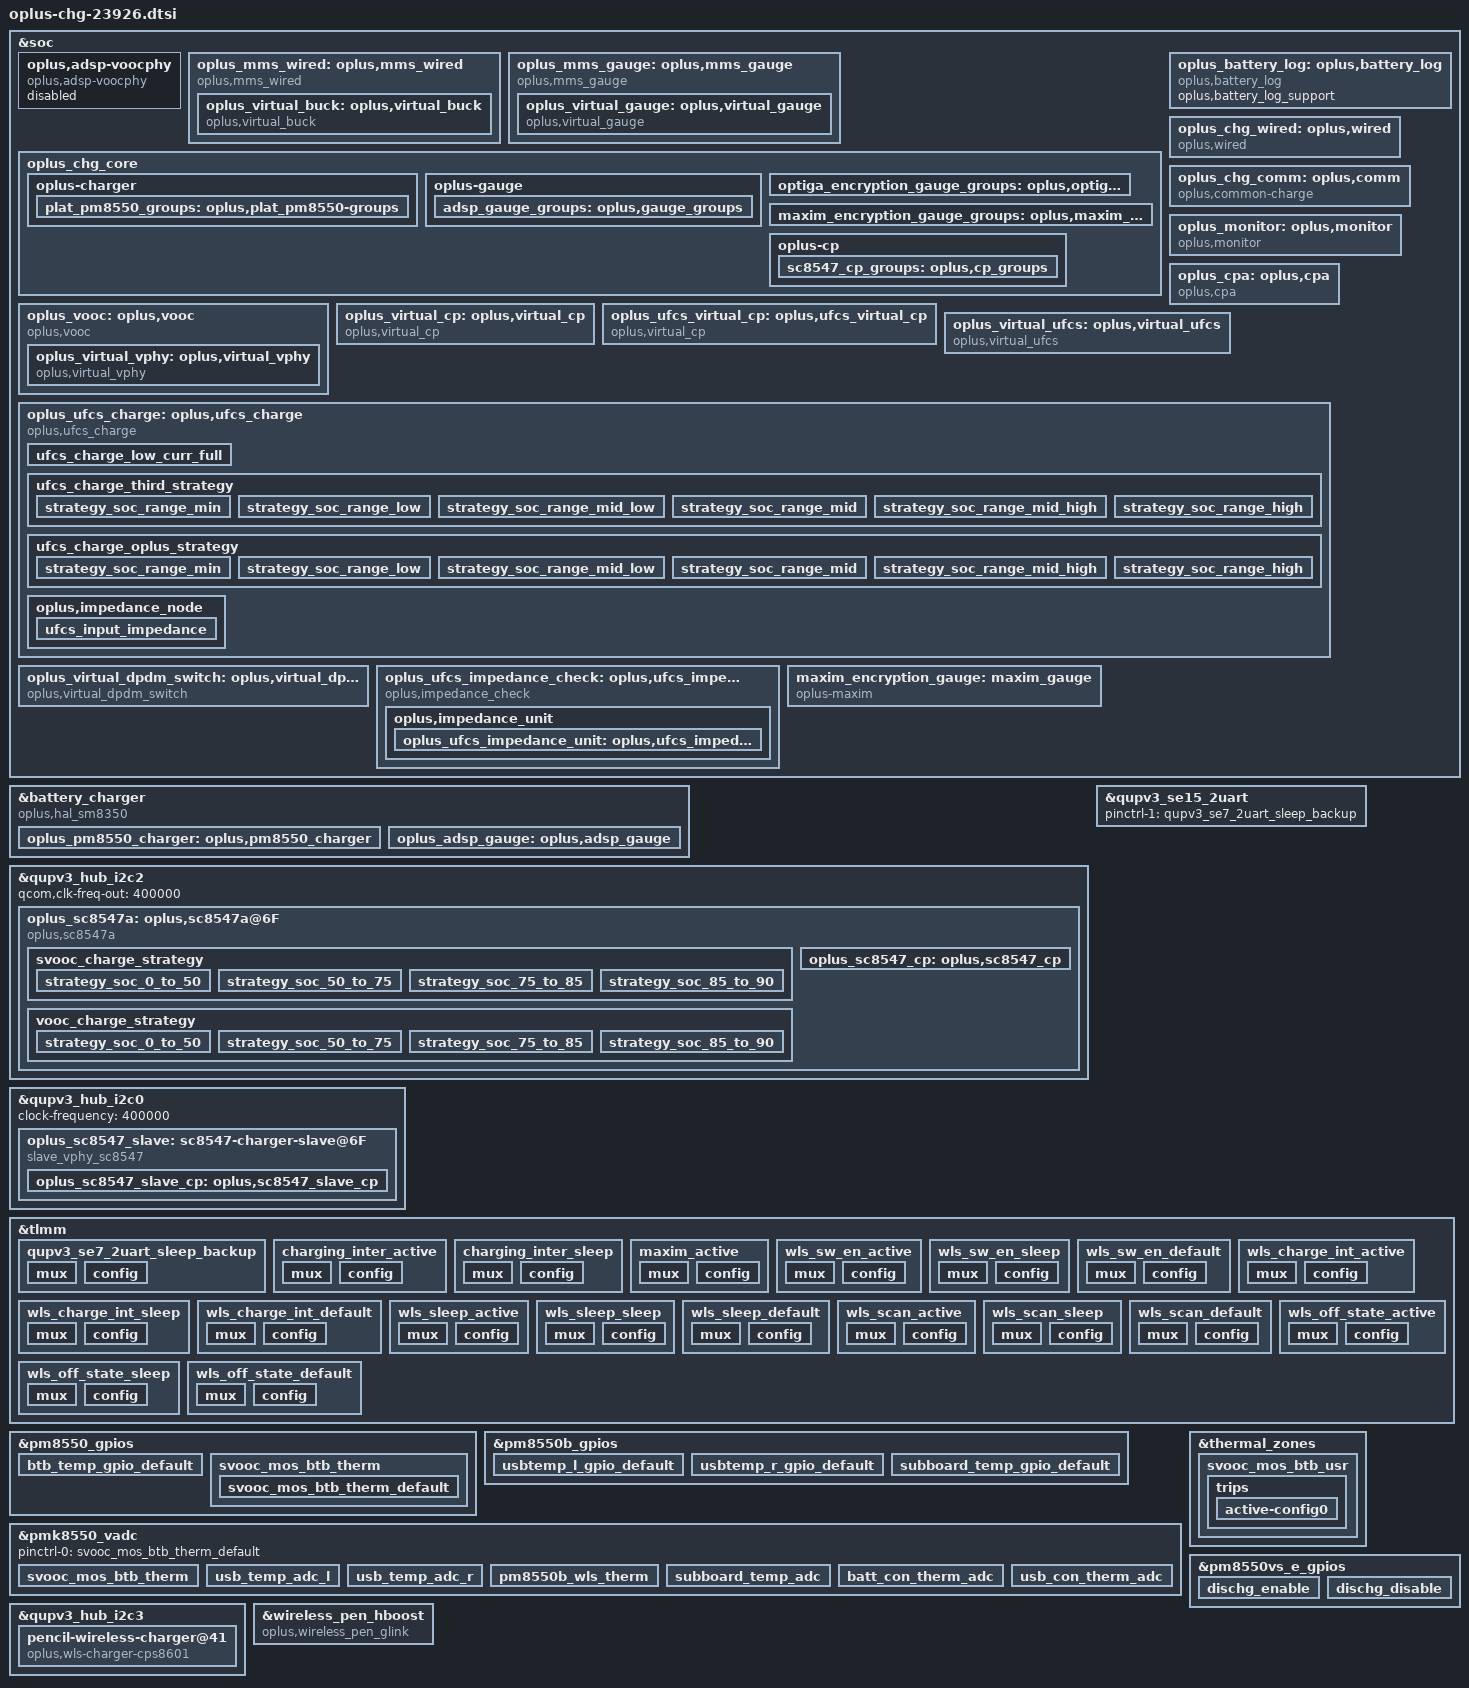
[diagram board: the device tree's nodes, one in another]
//ifdef OPLUS_FEATURE_CHG_BASIC
//BSP.CHG.Basic, 2023/12/22,  Add for charging

#include "oplus-chg-8650.h.dtsi"

&soc {
	oplus,adsp-voocphy {
		status = "disabled";
		compatible = "oplus,adsp-voocphy";
	};

	oplus_mms_wired: oplus,mms_wired {
		compatible = "oplus,mms_wired";
		oplus,buck_ic = <&oplus_virtual_buck>;
		oplus,voocphy_ic = <&oplus_virtual_vphy>;
		oplus,usbtemp_batttemp_gap = <12>;
		oplus,adc_info_name = "855";
		oplus,topic-update-interval = <5000>;

		/* High temperature long-term solution for Battery bulge*/
		high-temp-scheme;
		oplus,support_usbtemp_protect_v2;
		oplus_spec,usbtemp_batt_temp_low = <50>;
		oplus_spec,usbtemp_batt_temp_high = <50>;
		oplus_spec,usbtemp_batt_temp_over_hot = <60>;
		oplus_spec,usbtemp_ntc_temp_low = <57>;
		oplus_spec,usbtemp_ntc_temp_high = <69>;
		oplus_spec,usbtemp_temp_gap_low_with_batt_temp = <7>;
		oplus_spec,usbtemp_temp_gap_with_batt_temp_in_over_hot = <15>;
		oplus_spec,usbtemp_temp_gap_high_with_batt_temp = <12>;
		oplus_spec,usbtemp_temp_gap_low_without_batt_temp = <12>;
		oplus_spec,usbtemp_temp_gap_high_without_batt_temp = <24>;
		oplus_spec,usbtemp_rise_fast_temp_low = <3>;
		oplus_spec,usbtemp_rise_fast_temp_high = <3>;
		oplus_spec,usbtemp_rise_fast_temp_count_low = <30>;
		oplus_spec,usbtemp_rise_fast_temp_count_high = <20>;
		oplus_spec,usbtemp_cool_down_ntc_low = <54>;
		oplus_spec,usbtemp_cool_down_ntc_high = <65>;
		oplus_spec,usbtemp_cool_down_gap_low = <12>;
		oplus_spec,usbtemp_cool_down_gap_high = <20>;
		oplus_spec,usbtemp_cool_down_recover_ntc_low = <48>;
		oplus_spec,usbtemp_cool_down_recover_ntc_high = <60>;
		oplus_spec,usbtemp_cool_down_recover_gap_low = <6>;
		oplus_spec,usbtemp_cool_down_recover_gap_high = <15>;

		oplus_virtual_buck: oplus,virtual_buck {
			compatible = "oplus,virtual_buck";
			oplus,buck_ic = <&oplus_pm8550_charger>;
			oplus,buck_ic_index = <0>;
			oplus,buck_ic_connect = <OPLUS_CHG_IC_CONNECT_PARALLEL>;
			oplus,main_charger = <0>;
			oplus,buck_ic_current_ratio = <100>;
			oplus,buck_ic_func_group = <&plat_pm8550_groups>;

			oplus,ic_type = <OPLUS_CHG_IC_VIRTUAL_BUCK>;
			oplus,ic_index = <0>;

			oplus,uart_tx-gpio = <&tlmm 30 0x00>;
			oplus,uart_rx-gpio = <&tlmm 31 0x00>;

			oplus,dischg-gpio = <&pm8550vs_e_gpios 6 0x00>;

			pinctrl-names = "usbtemp_l_gpio_default", "usbtemp_r_gpio_default",
					"dischg_enable", "dischg_disable";
			pinctrl-0 = <&usbtemp_l_gpio_default>;
			pinctrl-1 = <&usbtemp_r_gpio_default>;
			pinctrl-2 = <&dischg_enable>;
			pinctrl-3 = <&dischg_disable>;


			io-channels = <&pmk8550_vadc PM8550B_ADC5_GEN3_AMUX2_GPIO5_100K_PU>,
							<&pmk8550_vadc PM8550B_ADC5_GEN3_AMUX_THM6_GPIO10_100K_PU>;
			io-channel-names = "usb_temp_adc_l", "usb_temp_adc_r";
		};
	};

	oplus_mms_gauge: oplus,mms_gauge {
		compatible = "oplus,mms_gauge";
		oplus,gauge_ic = <&oplus_virtual_gauge>;
		oplus,voocphy_ic = <&oplus_virtual_vphy>;
		oplus,topic-update-interval = <5000>;
		oplus,support_subboard_ntc;

		oplus_virtual_gauge: oplus,virtual_gauge {
			compatible = "oplus,virtual_gauge";
			oplus,gauge_ic = <&oplus_adsp_gauge &maxim_encryption_gauge>;
			oplus,gauge_ic_index = <0 1>;
			oplus,gauge_ic_func_group = <&adsp_gauge_groups &maxim_encryption_gauge_groups>;
			oplus,batt_capacity_mah = <9230>;
			oplus,ic_type = <OPLUS_CHG_IC_VIRTUAL_GAUGE>;
			oplus,ic_index = <0>;
		};
	};

	oplus_chg_core {
		oplus,chg_framework_v2;
		oplus,smart_charging_screenoff;
		oplus,common-charge-icl-support;

		oplus-charger {
			plat_pm8550_groups: oplus,plat_pm8550-groups {
				functions = <
					OPLUS_IC_FUNC_INIT
					OPLUS_IC_FUNC_EXIT
					OPLUS_IC_FUNC_REG_DUMP
					OPLUS_IC_FUNC_SMT_TEST
					OPLUS_IC_FUNC_BUCK_INPUT_PRESENT
					OPLUS_IC_FUNC_BUCK_INPUT_SUSPEND
					OPLUS_IC_FUNC_BUCK_INPUT_IS_SUSPEND
					OPLUS_IC_FUNC_BUCK_OUTPUT_SUSPEND
					OPLUS_IC_FUNC_BUCK_OUTPUT_IS_SUSPEND
					OPLUS_IC_FUNC_BUCK_GET_CC_ORIENTATION
					OPLUS_IC_FUNC_BUCK_GET_CHARGER_TYPE
					OPLUS_IC_FUNC_BUCK_RERUN_BC12
					OPLUS_IC_FUNC_BUCK_QC_DETECT_ENABLE
					OPLUS_IC_FUNC_BUCK_SHIPMODE_ENABLE
					OPLUS_IC_FUNC_BUCK_SET_QC_CONFIG
					OPLUS_IC_FUNC_BUCK_SET_PD_CONFIG
					OPLUS_IC_FUNC_GET_SHUTDOWN_SOC
					OPLUS_IC_FUNC_BACKUP_SOC
					OPLUS_IC_FUNC_GET_TYPEC_MODE
					OPLUS_IC_FUNC_BUCK_SET_ICL
					OPLUS_IC_FUNC_BUCK_GET_ICL
					OPLUS_IC_FUNC_BUCK_SET_FCC
					OPLUS_IC_FUNC_BUCK_SET_FV
					OPLUS_IC_FUNC_BUCK_SET_ITERM
					OPLUS_IC_FUNC_BUCK_SET_RECHG_VOL
					OPLUS_IC_FUNC_BUCK_GET_INPUT_CURR
					OPLUS_IC_FUNC_BUCK_GET_INPUT_VOL
					OPLUS_IC_FUNC_GET_CHARGER_CYCLE
					OPLUS_IC_FUNC_BUCK_GET_VBUS_COLLAPSE_STATUS
					OPLUS_IC_FUNC_GET_OTG_ENABLE
					OPLUS_IC_FUNC_OTG_BOOST_ENABLE
					OPLUS_IC_FUNC_SET_OTG_SWITCH_STATUS
					OPLUS_IC_FUNC_GET_OTG_SWITCH_STATUS
					OPLUS_IC_FUNC_GET_OTG_ONLINE_STATUS
					OPLUS_IC_FUNC_BUCK_GET_HW_DETECT
					OPLUS_IC_FUNC_VOOCPHY_SET_MATCH_TEMP
					OPLUS_IC_FUNC_IS_OPLUS_SVID
					OPLUS_IC_FUNC_BUCK_DIS_INSERT_DETECT
					OPLUS_IC_FUNC_GET_TYPEC_ROLE
					OPLUS_IC_FUNC_SET_TYPEC_MODE
					OPLUS_IC_FUNC_BUCK_GET_USB_BTB_TEMP
					OPLUS_IC_FUNC_BUCK_GET_BATT_BTB_TEMP
					OPLUS_IC_FUNC_BUCK_GET_USB_AICL_ENHANCE
					OPLUS_IC_FUNC_BUCK_SET_AICL_POINT
				>;
				virqs = <
					OPLUS_IC_VIRQ_ERR
					OPLUS_IC_VIRQ_CC_DETECT
					OPLUS_IC_VIRQ_PLUGIN
					OPLUS_IC_VIRQ_CC_CHANGED
					OPLUS_IC_VIRQ_SUSPEND_CHECK
					OPLUS_IC_VIRQ_CHG_TYPE_CHANGE
					OPLUS_IC_VIRQ_OTG_ENABLE
					OPLUS_IC_VIRQ_SVID
				>;
			};
		};

		oplus-gauge {
			adsp_gauge_groups: oplus,gauge_groups {
				functions = <
					OPLUS_IC_FUNC_INIT
					OPLUS_IC_FUNC_EXIT
					OPLUS_IC_FUNC_REG_DUMP
					OPLUS_IC_FUNC_SMT_TEST
					OPLUS_IC_FUNC_GAUGE_GET_BATT_VOL
					OPLUS_IC_FUNC_GAUGE_GET_BATT_MAX
					OPLUS_IC_FUNC_GAUGE_GET_BATT_MIN
					OPLUS_IC_FUNC_GAUGE_GET_BATT_CURR
					OPLUS_IC_FUNC_GAUGE_GET_BATT_TEMP
					OPLUS_IC_FUNC_GAUGE_GET_BATT_SOC
					OPLUS_IC_FUNC_GAUGE_GET_BATT_FCC
					OPLUS_IC_FUNC_GAUGE_GET_BATT_CC
					OPLUS_IC_FUNC_GAUGE_GET_BATT_RM
					OPLUS_IC_FUNC_GAUGE_GET_BATT_SOH
					OPLUS_IC_FUNC_GAUGE_GET_BATT_HMAC
					OPLUS_IC_FUNC_GAUGE_SET_BATT_FULL
					OPLUS_IC_FUNC_GAUGE_UPDATE_DOD0
					OPLUS_IC_FUNC_GAUGE_UPDATE_SOC_SMOOTH
					OPLUS_IC_FUNC_GAUGE_GET_CB_STATUS
					OPLUS_IC_FUNC_GAUGE_GET_BATT_NUM
					OPLUS_IC_FUNC_GAUGE_GET_DEVICE_TYPE
					OPLUS_IC_FUNC_GAUGE_GET_DEVICE_TYPE_FOR_VOOC
					OPLUS_IC_FUNC_GAUGE_GET_BATT_FCC
					OPLUS_IC_FUNC_GAUGE_UPDATE
					OPLUS_IC_FUNC_GAUGE_IS_SUSPEND
					OPLUS_IC_FUNC_GAUGE_GET_SUBBOARD_TEMP
					OPLUS_IC_FUNC_GAUGE_GET_BCC_PARMS
					OPLUS_IC_FUNC_GAUGE_GET_DEVICE_TYPE_FOR_BCC
					OPLUS_IC_FUNC_GAUGE_GET_DOD0
					OPLUS_IC_FUNC_GAUGE_GET_DOD0_PASSED_Q
					OPLUS_IC_FUNC_GAUGE_GET_QMAX
					OPLUS_IC_FUNC_GAUGE_GET_QMAX_PASSED_Q
				>;
				virqs = <
					OPLUS_IC_VIRQ_ERR
					OPLUS_IC_VIRQ_OFFLINE
					OPLUS_IC_VIRQ_RESUME
				>;
			};
		};

		optiga_encryption_gauge_groups: oplus,optiga_encryption_gauge_groups {
			functions = <
				OPLUS_IC_FUNC_INIT
				OPLUS_IC_FUNC_EXIT
				OPLUS_IC_FUNC_GAUGE_GET_BATT_AUTH
			>;
			virqs = <
				OPLUS_IC_VIRQ_ERR
			>;
		};

		maxim_encryption_gauge_groups: oplus,maxim_encryption_gauge_groups {
			functions = <
				OPLUS_IC_FUNC_INIT
				OPLUS_IC_FUNC_EXIT
				OPLUS_IC_FUNC_GAUGE_GET_BATT_AUTH
			>;
			virqs = <
				OPLUS_IC_VIRQ_ERR
			>;
		};

		oplus-cp {
			sc8547_cp_groups: oplus,cp_groups {
			functions = <
					OPLUS_IC_FUNC_INIT
					OPLUS_IC_FUNC_EXIT
					OPLUS_IC_FUNC_REG_DUMP
					OPLUS_IC_FUNC_SMT_TEST
					OPLUS_IC_FUNC_CP_ENABLE
					OPLUS_IC_FUNC_CP_HW_INTI
					OPLUS_IC_FUNC_CP_SET_WORK_START
					OPLUS_IC_FUNC_CP_CHECK_WORK_MODE_SUPPORT
					OPLUS_IC_FUNC_CP_SET_WORK_MODE
					OPLUS_IC_FUNC_CP_GET_WORK_MODE
					OPLUS_IC_FUNC_CP_GET_VIN
					OPLUS_IC_FUNC_CP_GET_IIN
					OPLUS_IC_FUNC_CP_SET_IIN
					OPLUS_IC_FUNC_CP_GET_VOUT
					OPLUS_IC_FUNC_CP_GET_IOUT
					OPLUS_IC_FUNC_CP_GET_VAC
					OPLUS_IC_FUNC_CP_GET_WORK_STATUS
					OPLUS_IC_FUNC_CP_SET_ADC_ENABLE
					OPLUS_IC_FUNC_CP_WATCHDOG_ENABLE
				>;
				virqs = <
					OPLUS_IC_VIRQ_ERR
					OPLUS_IC_VIRQ_ONLINE
					OPLUS_IC_VIRQ_OFFLINE
				>;
			};
		};
	};

	oplus_battery_log: oplus,battery_log {
		compatible = "oplus,battery_log";

		oplus,battery_log_support;
	};

	oplus_chg_wired: oplus,wired {
		compatible = "oplus,wired";

		oplus,vooc-support;

		oplus_spec,vbatt_pdqc_to_5v_thr = <5100>;
		oplus_spec,vbatt_pdqc_to_9v_thr = <5100>;
		oplus_spec,pd-iclmax-ma = <2000>;
		oplus_spec,qc-iclmax-ma = <2000>;
		oplus_spec,non-standard-ibatmax-ma = <500>;
		oplus_spec,input-power-mw = <
			2500		/* OPLUS_WIRED_CHG_MODE_UNKNOWN */
			2500		/* OPLUS_WIRED_CHG_MODE_SDP */
			7500		/* OPLUS_WIRED_CHG_MODE_CDP */
			10000		/* OPLUS_WIRED_CHG_MODE_DCP */
			15000		/* OPLUS_WIRED_CHG_MODE_VOOC */
			18000		/* OPLUS_WIRED_CHG_MODE_QC */
			18000		/* OPLUS_WIRED_CHG_MODE_PD */
		>;
		oplus_spec,led_on-fccmax-ma = <0 1140 4000 4000 4000 4000 1000 0>;
		oplus_spec,fccmax-ma-lv = <
			0 1200 2200 2200 2200 2200 2200 0	/* OPLUS_WIRED_CHG_MODE_UNKNOWN */
			0 600  600  600  600  600  600  0	/* OPLUS_WIRED_CHG_MODE_SDP */
			0 1200 1600 1600 1600 1600 1600 0	/* OPLUS_WIRED_CHG_MODE_CDP */
			0 1200 2200 2200 2200 2200 2200 0	/* OPLUS_WIRED_CHG_MODE_DCP */
			0 1200 3600 3600 3600 3600 2200 0	/* OPLUS_WIRED_CHG_MODE_VOOC */
			0 1200 4000 4000 4000 4000 2200 0	/* OPLUS_WIRED_CHG_MODE_QC */
			0 1200 4000 4000 4000 4000 2200 0	/* OPLUS_WIRED_CHG_MODE_PD */
		>;
		oplus_spec,fccmax-ma-hv = <
			0 1200 2200 2200 2200 2200 2200 0	/* OPLUS_WIRED_CHG_MODE_UNKNOWN */
			0 600  600  600  600  600  600  0	/* OPLUS_WIRED_CHG_MODE_SDP */
			0 1200 1600 1600 1600 1600 1600 0	/* OPLUS_WIRED_CHG_MODE_CDP */
			0 1200 2200 2200 2200 2200 2200 0	/* OPLUS_WIRED_CHG_MODE_DCP */
			0 1200 3600 3600 3600 3600 2200 0	/* OPLUS_WIRED_CHG_MODE_VOOC */
			0 1200 4000 4000 4000 4000 2200 0	/* OPLUS_WIRED_CHG_MODE_QC */
			0 1200 4000 4000 4000 4000 2200 0	/* OPLUS_WIRED_CHG_MODE_PD */
		>;

		oplus_spec,cool_down_pdqc_vol_mv = <5000 5000 5000 9000 9000>;
		oplus_spec,cool_down_pdqc_curr_ma = <1200 1500 2000 1500 2000>;
		oplus_spec,cool_down_vooc_curr_ma = <1200 1500 2000 2500 3000 3000>;
		oplus_spec,cool_down_normal_curr_ma = <1200 1500 2000>;

		oplus_spec,vbus_ov_thr_mv = <10200 10200>;
		oplus_spec,vbus_uv_thr_mv = <4300 4300>;

		/* first data is strategy used temp type */
		oplus,vooc_strategy_name = "cgcl";
		oplus,vooc_strategy_data = <OPLUS_STRATEGY_USE_BATT_TEMP
					    0   350 3000 1 0
					    330 370 3000 2 0
					    350 440 2200 2 1>;
	};

	oplus_chg_comm: oplus,comm {
		compatible = "oplus,common-charge";
		oplus_spec,batt-them-thr = <(-100) 0 50 120 160 450 530>;
		oplus_spec,iterm-ma = <500>; /* 2220*0.05+10 */
		oplus_spec,removed_bat_decidegc = <390>; /*-39 degree*/
		oplus_spec,fv-mv = <0 4430 4455 4455 4455 4455 4130 4130>;
		oplus_spec,sw-fv-mv = <0 4420 4420 4420 4420 4420 4080 4080>;
		oplus_spec,hw-fv-inc-mv = <0 18 18 18 18 18 18 0>;
		oplus_spec,sw-over-fv-mv = <0 4440 4465 4465 4465 4465 4140 4140>;
		oplus_spec,sw-over-fv-dec-mv = <8>;
		oplus_spec,non-standard-sw-fv-mv = <3930>;
		oplus_spec,non-standard-fv-mv = <3980>;
		oplus_spec,non-standard-hw-fv-inc-mv = <18>;
		oplus_spec,non-standard-sw-over-fv-mv = <3990>;
		oplus_spec,non-standard-vbatdet-mv = <3600>;
		oplus_spec,wired-vbatdet-mv = <0 4130 4265 4365 4365 4365 4030 0>;
		oplus_spec,fcc-gear-thr-mv = <4180>;
		oplus_spec,vbatt-ov-thr-mv = <4600>;

		oplus_spec,full_pre_ffc_judge;
		oplus_spec,full-pre-ffc-mv = <4435>;
		oplus_spec,ffc-temp-thr = <120 350 400>;
		oplus_spec,wired-ffc-step-max = <2>;
		oplus_spec,wired-ffc-fv-mv = <4590 4590>;

		oplus_spec,wired-ffc-fv-cutoff-mv = <4485 4485 4485 4485>;
		oplus_spec,wired-ffc-fcc-ma = <1700 1700
					       1600 1600>;
		oplus_spec,wired-ffc-fcc-cutoff-ma = <1500 1500
						      1400 1400>;
		/* 2s battery */
		oplus_spec,wired-aging-ffc-version = <AGING_FFC_V1>;
		oplus_spec,wired-aging-ffc-offset-mv = <15 30 10 20>;
		oplus_spec,wired-aging-ffc-cycle-thr = <500 1000>;
		oplus_spec,vbat_uv_thr_mv = <3300>;
		oplus_spec,vbat_charging_uv_thr_mv = <3200>;

		/*If use subboard NTC as battery temp, config it as 20, otherwise 0 */
		oplus_spec,tbatt_power_off_cali_temp = <0>;
		oplus,vooc_show_ui_soc_decimal;
		oplus_spec,poweroff_high_batt_temp = <720>;
		oplus_spec,poweroff_emergency_batt_temp = <770>;
		oplus,ui_soc_decimal_speedmin = <20>;
		oplus,gauge_stuck_jump_support;
		oplus,gauge_stuck_threshold = <15>;
		oplus,gauge_stuck_time = <50>;
		oplus,smooth_switch;
		oplus,reserve_chg_soc = <3>;

		oplus_spec,batt_full_time = <300>;
	};

	oplus_monitor: oplus,monitor {
		compatible = "oplus,monitor";
		oplus,topic-update-interval = <60000>;

		track,fast_chg_break_t_thd = <1000>;
		track,general_chg_break_t_thd = <200>;
		track,voocphy_type = <2>;
		track,wired_max_power = <67000>;
		track,wired_fast_chg_scheme = <2>;
	};

	oplus_vooc: oplus,vooc {
		compatible = "oplus,vooc";
		oplus,vooc_ic = <&oplus_virtual_vphy>;

		oplus_spec,vooc_soc_range = <50 75 85>;
		oplus_spec,vooc_temp_range = <50 120 180 350 450>;

		oplus,vooc_data_width = <7>;
		oplus,vooc_curr_max = <CP_CURR_LIMIT_7BIT_12_6A>; /* 67W: 11V 6.1A(IBUS *2) */
		oplus,vooc_power_max_w = <67>;
		oplus,vooc_project = <13>;
		oplus,vooc_curr_table_type = <VOOC_CP_CURR_TABLE>;
		oplus,voocphy_support = <3>; /* AP_DUAL_CP_VOOCPHY */
		oplus,support_fake_vooc_check;
		oplus,subboard_ntc_abnormal_current = <4000>;

		oplus,abnormal_adapter_current = <CP_CURR_LIMIT_7BIT_12_6A CP_CURR_LIMIT_7BIT_12_6A
						CP_CURR_LIMIT_7BIT_10_0A CP_CURR_LIMIT_7BIT_10_0A
						CP_CURR_LIMIT_7BIT_8_0A CP_CURR_LIMIT_7BIT_8_0A
						CP_CURR_LIMIT_7BIT_6_0A CP_CURR_LIMIT_7BIT_6_0A
						CP_CURR_LIMIT_7BIT_4_0A CP_CURR_LIMIT_7BIT_4_0A>;

		/* first data is strategy used temp type */
		oplus,general_strategy_name = "cgcl";
		oplus,general_strategy_data = < OPLUS_STRATEGY_USE_SHELL_TEMP
						0   385 CP_CURR_LIMIT_7BIT_12_6A 1 0
						389 395 CP_CURR_LIMIT_7BIT_10_0A 2 0
						398 420 CP_CURR_LIMIT_7BIT_8_0A 3 1
						405 440 CP_CURR_LIMIT_7BIT_6_0A 3 2 >;

		oplus_virtual_vphy: oplus,virtual_vphy {
			compatible = "oplus,virtual_vphy";
			oplus,vphy_ic = <&oplus_sc8547a>;
			oplus,dpdm_switch_ic = <&oplus_virtual_dpdm_switch>;

			oplus,ic_type = <OPLUS_CHG_IC_VIRTUAL_VPHY>;
			oplus,ic_index = <0>;
		};
	};

	oplus_cpa: oplus,cpa {
		compatible = "oplus,cpa";
	oplus,protocol_list = <CHG_PROTOCOL_UFCS 33
				CHG_PROTOCOL_PD   18
				CHG_PROTOCOL_VOOC 67
				CHG_PROTOCOL_QC   18>;
	oplus,default_protocol_list = <CHG_PROTOCOL_UFCS
					CHG_PROTOCOL_PD
					CHG_PROTOCOL_VOOC>;
	};

	oplus_virtual_cp: oplus,virtual_cp {
		compatible = "oplus,virtual_cp";

		oplus,ic_type = <OPLUS_CHG_IC_VIRTUAL_CP>;
		oplus,ic_index = <0>;

		oplus,cp_ic = <&oplus_sc8547_cp &oplus_sc8547_slave_cp>;
		oplus,input_curr_max_ma = <3000 3000>;

		oplus,cp_ic_connect = <OPLUS_CHG_IC_CONNECT_PARALLEL>;
		oplus,main_cp = <0>;

		oplus,reg_proc_node;
	};

	oplus_ufcs_virtual_cp: oplus,ufcs_virtual_cp {
		compatible = "oplus,virtual_cp";

		oplus,ic_type = <OPLUS_CHG_IC_VIRTUAL_CP>;
		oplus,ic_index = <1>;

		oplus,cp_ic = <&oplus_virtual_cp>;
		oplus,input_curr_max_ma = <3000>;

		oplus,cp_ic_connect = <OPLUS_CHG_IC_CONNECT_PARALLEL>;
		oplus,main_cp = <0>;
	};

	oplus_virtual_ufcs: oplus,virtual_ufcs {
		compatible = "oplus,virtual_ufcs";

		oplus,ic_type = <OPLUS_CHG_IC_VIRTUAL_UFCS>;
		oplus,ic_index = <0>;
	};

	oplus_ufcs_charge: oplus,ufcs_charge {
		compatible = "oplus,ufcs_charge";
		oplus,ufcs_ic = <&oplus_virtual_ufcs>;
		oplus,cp_ic = <&oplus_virtual_cp>;
		oplus,dpdm_switch_ic = <&oplus_virtual_dpdm_switch>;

		oplus,impedance_unit = <&oplus_ufcs_impedance_unit>;

		oplus,target_vbus_mv = <11000>;
		oplus,curr_max_ma = <3000>;

		oplus,ufcs_warm_allow_vol = <4000>;
		oplus,ufcs_warm_allow_soc = <50>;
		oplus,ufcs_strategy_normal_current = <3000>;//6A
		oplus,ufcs_over_high_or_low_current = <3000>;
		oplus,ufcs_timeout_third = <10800>;
		oplus,ufcs_timeout_oplus = <10800>;
		oplus,ufcs_ibat_over_third = <7000>;
		oplus,ufcs_ibat_over_oplus = <7000>;
		oplus,ufcs_full_cool_sw_vbat = <4480>;
		oplus,ufcs_full_normal_sw_vbat = <4500>;
		oplus,ufcs_full_normal_hw_vbat = <4510>;
		oplus,ufcs_full_ffc_vbat = <4520>;
		oplus,ufcs_full_warm_vbat = <4130>;
		oplus,ufcs_full_cool_sw_vbat_third = <4470>;
		oplus,ufcs_full_normal_sw_vbat_third= <4470>;
		oplus,ufcs_full_normal_hw_vbat_third = <4480>;
		oplus,ufcs_current_change_timeout = <100>;
		oplus,ufcs_strategy_batt_high_temp = <410 420 430 400 410 420>;
		oplus,ufcs_strategy_high_current = <2000 2000 2000 3000 3000 3000>;
		oplus,ufcs_charge_strategy_soc = <0 20 35 50 75 85 95>;
		oplus,ufcs_charge_strategy_temp = <0 50 120 200 350 440 530>;
		oplus,ufcs_low_curr_full_strategy_temp = <0 200 350 440>;

		ufcs_charge_low_curr_full {
			strategy_temp_little_cool = 	<1500 4490 0
							 1400 4480 0
							 1300 4470 0
							 1200 4460 0
							 1100  4450 1>;
			strategy_temp_normal_low =	<1500 4490 0
                                                         1400 4480 0
                                                         1300 4470 0
                                                         1200 4460 0
                                                         1100  4450 1>;
			strategy_temp_normal_high = 	<1600 4490 0
                                                         1400 4480 0
                                                         1300 4470 0
                                                         1200 4460 0
                                                         1100  4450 1>;
		};

		ufcs_charge_third_strategy {
			oplus,temp_type = <OPLUS_STRATEGY_USE_SHELL_TEMP>;
			oplus,soc_range = <0 20 35 50 75 85 95>;
			oplus,temp_range = <0 50 120 200 350 440 530>;

			strategy_soc_range_min {
				strategy_temp_little_cold =	<11000 4455 2500 0 0
								11000 4455 2000 0 0
								11000 4455 1500 0 0
								11000 4465 1000 1 0>;
				strategy_temp_cool =		<11000 4455 3000 0 0
								11000 4455 2500 0 0
								11000 4455 2000 0 0
								11000 4455 1500 0 0
								11000 4465 1000 1 0>;
				strategy_temp_little_cool =	<11000 4460 3000 0 0
								11000 4460 2500 0 0
								11000 4460 2000 0 0
								11000 4460 1500 0 0
								11000 4470 1000 1 0>;
				strategy_temp_normal_low =	<11000 4460 3000 0 0
								11000 4460 2500 0 0
								11000 4460 2000 0 0
								11000 4460 1500 0 0
								11000 4470 1000 1 0>;
				strategy_temp_normal_high =	<11000 4460 3000 0 0
								11000 4460 2500 0 0
								11000 4460 2000 0 0
								11000 4460 1500 0 0
								11000 4470 1000 1 0>;
				strategy_temp_warm =		<11000 4130 1000 1 0>;
			};
			strategy_soc_range_low {
				strategy_temp_little_cold =	<11000 4455 2500 0 0
								11000 4455 2000 0 0
								11000 4455 1500 0 0
								11000 4465 1000 1 0>;
				strategy_temp_cool =		<11000 4455 3000 0 0
								11000 4455 2500 0 0
								11000 4455 2000 0 0
								11000 4455 1500 0 0
								11000 4465 1000 1 0>;
				strategy_temp_little_cool =	<11000 4460 3000 0 0
								11000 4460 2500 0 0
								11000 4460 2000 0 0
								11000 4460 1500 0 0
								11000 4470 1000 1 0>;
				strategy_temp_normal_low =	<11000 4460 3000 0 0
								11000 4460 2500 0 0
								11000 4460 2000 0 0
								11000 4460 1500 0 0
								11000 4470 1000 1 0>;
				strategy_temp_normal_high =	<11000 4460 3000 0 0
								11000 4460 2500 0 0
								11000 4460 2000 0 0
								11000 4460 1500 0 0
								11000 4470 1000 1 0>;
				strategy_temp_warm =		<11000 4130 1000 1 0>;
			};
			strategy_soc_range_mid_low {
				strategy_temp_little_cold =	<11000 4455 2500 0 0
								11000 4455 2000 0 0
								11000 4455 1500 0 0
								11000 4465 1000 1 0>;
				strategy_temp_cool =		<11000 4455 3000 0 0
								11000 4455 2500 0 0
								11000 4455 2000 0 0
								11000 4455 1500 0 0
								11000 4465 1000 1 0>;
				strategy_temp_little_cool =	<11000 4460 3000 0 0
								11000 4460 2500 0 0
								11000 4460 2000 0 0
								11000 4460 1500 0 0
								11000 4470 1000 1 0>;
				strategy_temp_normal_low =	<11000 4460 3000 0 0
								11000 4460 2500 0 0
								11000 4460 2000 0 0
								11000 4460 1500 0 0
								11000 4470 1000 1 0>;
				strategy_temp_normal_high =	<11000 4460 3000 0 0
								11000 4460 2500 0 0
								11000 4460 2000 0 0
								11000 4460 1500 0 0
								11000 4470 1000 1 0>;
				strategy_temp_warm =		<11000 4130 1000 1 0>;
			};
			strategy_soc_range_mid {
				strategy_temp_little_cold =	<11000 4455 2500 0 0
								11000 4455 2000 0 0
								11000 4455 1500 0 0
								11000 4465 1000 1 0>;
				strategy_temp_cool =		<11000 4455 3000 0 0
								11000 4455 2500 0 0
								11000 4455 2000 0 0
								11000 4455 1500 0 0
								11000 4465 1000 1 0>;
				strategy_temp_little_cool =	<11000 4460 3000 0 0
								11000 4460 2500 0 0
								11000 4460 2000 0 0
								11000 4460 1500 0 0
								11000 4470 1000 1 0>;
				strategy_temp_normal_low =	<11000 4460 3000 0 0
								11000 4460 2500 0 0
								11000 4460 2000 0 0
								11000 4460 1500 0 0
								11000 4470 1000 1 0>;
				strategy_temp_normal_high =	<11000 4460 3000 0 0
								11000 4460 2500 0 0
								11000 4460 2000 0 0
								11000 4460 1500 0 0
								11000 4470 1000 1 0>;
				strategy_temp_warm =		<11000 4130 1000 1 0>;
			};
			strategy_soc_range_mid_high {
				strategy_temp_little_cold =	<11000 4455 2000 0 0
								11000 4455 1500 0 0
								11000 4465 1000 1 0>;
				strategy_temp_cool =		<11000 4455 2000 0 0
								11000 4455 1500 0 0
								11000 4465 1000 1 0>;
				strategy_temp_little_cool =	<11000 4460 2000 0 0
								11000 4460 1500 0 0
								11000 4470 1000 1 0>;
				strategy_temp_normal_low =	<11000 4460 2000 0 0
								11000 4460 1500 0 0
								11000 4470 1000 1 0>;
				strategy_temp_normal_high =	<11000 4460 2000 0 0
								11000 4460 1500 0 0
								11000 4470 1000 1 0>;
				strategy_temp_warm =		<11000 4130 1000 1 0>;
			};
			strategy_soc_range_high {
				strategy_temp_little_cold =	<11000 4455 1500 0 0
								11000 4465 1000 1 0>;
				strategy_temp_cool =		<11000 4455 1500 0 0
								11000 4465 1000 1 0>;
				strategy_temp_little_cool =	<11000 4460 1500 0 0
								11000 4470 1000 1 0>;
				strategy_temp_normal_low =	<11000 4460 1500 0 0
								11000 4470 1000 1 0>;
				strategy_temp_normal_high =	<11000 4460 1500 0 0
								11000 4470 1000 1 0>;
				strategy_temp_warm =		<11000 4130 1000 1 0>;
			};
		};

		ufcs_charge_oplus_strategy {
			oplus,temp_type = <OPLUS_STRATEGY_USE_SHELL_TEMP>;
			oplus,soc_range = <0 20 35 50 75 85 95>;
			oplus,temp_range = <0 50 120 200 350 440 530>;
			strategy_soc_range_min {
				strategy_temp_little_cold =	<11000 4455 2500 0 0
								11000 4455 2000 0 0
								11000 4455 1500 0 0
								11000 4465 1000 1 0>;
				strategy_temp_cool =		<11000 4455 3000 0 0
								11000 4455 2500 0 0
								11000 4455 2000 0 0
								11000 4455 1500 0 0
								11000 4465 1000 1 0>;
				strategy_temp_little_cool =	<11000 4490 3000 0 0
								11000 4490 2500 0 0
								11000 4490 2000 0 0
								11000 4490 1500 0 0
								11000 4500 1000 1 0>;
				strategy_temp_normal_low =	<11000 4490 3000 0 0
								11000 4490 2500 0 0
								11000 4490 2000 0 0
								11000 4490 1500 0 0
								11000 4500 1000 1 0>;
				strategy_temp_normal_high =	<11000 4490 3000 0 0
								11000 4490 2500 0 0
								11000 4490 2000 0 0
								11000 4490 1500 0 0
								11000 4500 1000 1 0>;
				strategy_temp_warm =		<11000 4130 1000 1 0>;
			};
			strategy_soc_range_low {
				strategy_temp_little_cold =	<11000 4455 2500 0 0
								11000 4455 2000 0 0
								11000 4455 1500 0 0
								11000 4465 1000 1 0>;
				strategy_temp_cool =		<11000 4455 3000 0 0
								11000 4455 2500 0 0
								11000 4455 2000 0 0
								11000 4455 1500 0 0
								11000 4465 1000 1 0>;
				strategy_temp_little_cool =	<11000 4490 3000 0 0
								11000 4490 2500 0 0
								11000 4490 2000 0 0
								11000 4490 1500 0 0
								11000 4500 1000 1 0>;
				strategy_temp_normal_low =	<11000 4490 3000 0 0
								11000 4490 2500 0 0
								11000 4490 2000 0 0
								11000 4490 1500 0 0
								11000 4500 1000 1 0>;
				strategy_temp_normal_high =	<11000 4490 3000 0 0
								11000 4490 2500 0 0
								11000 4490 2000 0 0
								11000 4490 1500 0 0
								11000 4500 1000 1 0>;
				strategy_temp_warm =		<11000 4130 1000 1 0>;
			};
			strategy_soc_range_mid_low {
				strategy_temp_little_cold =	<11000 4455 2500 0 0
								11000 4455 2000 0 0
								11000 4455 1500 0 0
								11000 4465 1000 1 0>;
				strategy_temp_cool =		<11000 4455 3000 0 0
								11000 4455 2500 0 0
								11000 4455 2000 0 0
								11000 4455 1500 0 0
								11000 4465 1000 1 0>;
				strategy_temp_little_cool =	<11000 4490 3000 0 0
								11000 4490 2500 0 0
								11000 4490 2000 0 0
								11000 4490 1500 0 0
								11000 4500 1000 1 0>;
				strategy_temp_normal_low =	<11000 4490 3000 0 0
								11000 4490 2500 0 0
								11000 4490 2000 0 0
								11000 4490 1500 0 0
								11000 4510 1000 1 0>;
				strategy_temp_normal_high =	<11000 4490 3000 0 0
								11000 4490 2500 0 0
								11000 4490 2000 0 0
								11000 4490 1500 0 0
								11000 4500 1000 1 0>;
				strategy_temp_warm =		<11000 4130 1000 1 0>;
			};
			strategy_soc_range_mid {
				strategy_temp_little_cold =	<11000 4455 2500 0 0
								11000 4455 2000 0 0
								11000 4455 1500 0 0
								11000 4465 1000 1 0>;
				strategy_temp_cool =		<11000 4455 3000 0 0
								11000 4455 2500 0 0
								11000 4455 2000 0 0
								11000 4455 1500 0 0
								11000 4465 1000 1 0>;
				strategy_temp_little_cool =	<11000 4490 3000 0 0
								11000 4490 2500 0 0
								11000 4490 2000 0 0
								11000 4490 1500 0 0
								11000 4500 1000 1 0>;
				strategy_temp_normal_low =	<11000 4490 3000 0 0
								11000 4490 2500 0 0
								11000 4490 2000 0 0
								11000 4490 1500 0 0
								11000 4500 1000 1 0>;
				strategy_temp_normal_high =	<11000 4490 3000 0 0
								11000 4490 2500 0 0
								11000 4490 2000 0 0
								11000 4490 1500 0 0
								11000 4500 1000 1 0>;
				strategy_temp_warm =		<11000 4130 1000 1 0>;
			};
			strategy_soc_range_mid_high {
				strategy_temp_little_cold =	<11000 4455 2000 0 0
								11000 4455 1500 0 0
								11000 4465 1000 1 0>;
				strategy_temp_cool =		<11000 4455 2000 0 0
								11000 4455 1500 0 0
								11000 4465 1000 1 0>;
				strategy_temp_little_cool =	<11000 4490 2000 0 0
								11000 4490 1500 0 0
								11000 4500 1000 1 0>;
				strategy_temp_normal_low =	<11000 4490 2000 0 0
								11000 4490 1500 0 0
								11000 4500 1000 1 0>;
				strategy_temp_normal_high =	<11000 4490 2000 0 0
								11000 4490 1500 0 0
								11000 4500 1000 1 0>;
				strategy_temp_warm =		<11000 4130 1000 1 0>;
			};
			strategy_soc_range_high {
				strategy_temp_little_cold =	<11000 4455 1500 0 0
								11000 4465 1000 1 0>;
				strategy_temp_cool =		<11000 4455 1500 0 0
								11000 4465 1000 1 0>;
				strategy_temp_little_cool =	<11000 4490 1500 0 0
								11000 4500 1000 1 0>;
				strategy_temp_normal_low =	<11000 4490 1500 0 0
								11000 4500 1000 1 0>;
				strategy_temp_normal_high =	<11000 4490 1500 0 0
								11000 4500 1000 1 0>;
				strategy_temp_warm =		<11000 4130 1000 1 0>;
			};
		};

		oplus,impedance_node {
			ufcs_input_impedance: ufcs_input_impedance {
				node_name = "ufcs_input";
				default_impedance_mohm = <95>;
				default_curr_ma = <3000>;
				current_drop_table = <
					40  3000
					90  3000
					140 2000
					200 2000
					260 0
				>;
			};
		};
	};

	oplus_virtual_dpdm_switch: oplus,virtual_dpdm_switch {
		compatible = "oplus,virtual_dpdm_switch";

		oplus,ic_type = <OPLUS_CHG_IC_MISC>;
		oplus,ic_index = <0>;

		oplus,use_audio_switch;
	};
};

&soc {
	oplus_ufcs_impedance_check: oplus,ufcs_impedance_check {
		compatible = "oplus,impedance_check";

		oplus,impedance_unit {
			oplus_ufcs_impedance_unit: oplus,ufcs_impedance_unit {
				uint_name = "ufcs";
				default_curr_ma = <3000>;
				impedance_node = <&ufcs_input_impedance>;
			};
		};
	};
};

&battery_charger {
	//for oplus chg framework:
	oplus,chg_ops = "plat-pmic";
	qcom,pmic_ftm_vph = "/sys/bus/spmi/drivers/pmic-spmi/0-00/c42d000.qcom,spmi:qcom,pmk8550@0:vadc@9000/iio:device0/in_voltage_pm8550b_vph_pwr_input";
	qcom,pmic_ftm_vbat = "/sys/bus/spmi/drivers/pmic-spmi/0-00/c42d000.qcom,spmi:qcom,pmk8550@0:vadc@9000/iio:device0/in_voltage_pm8550b_vbat_sns_qbg_input";
};

&battery_charger {
	//for oplus chg framework:
	compatible = "oplus,hal_sm8350";

	pinctrl-names = "subboard_temp_gpio_default", "btb_temp_gpio_default";
	pinctrl-0 = <&subboard_temp_gpio_default>;
	pinctrl-1 = <&btb_temp_gpio_default>;
	oplus,usb_aicl_enhance;

	qcom,otg_boost_src = <0>;//0:plat_pmic 1:external
	oplus,batt_num = <1>;
	oplus,otg_scheme = <0>;//0:cid 1:ccdetect_gpio 2:switch
	oplus_pm8550_charger: oplus,pm8550_charger {
		oplus,ic_type = <OPLUS_CHG_IC_BUCK>;
		oplus,ic_index = <0>;
	};
	oplus_adsp_gauge: oplus,adsp_gauge {
		oplus,ic_type = <OPLUS_CHG_IC_GAUGE>;
		oplus,ic_index = <0>;
	};

};

&battery_charger {
	io-channels	= <&pmk8550_vadc PM8550B_ADC5_GEN3_AMUX3_GPIO6_100K_PU>,
					<&pmk8550_vadc PM8550B_ADC5_GEN3_AMUX_THM1_BATT_THERM_100K_PU>,
					<&pmk8550_vadc PM8550B_ADC5_GEN3_AMUX_THM4_USB_THERM_100K_PU>;
	io-channel-names = "subboard_temp_adc", "batt_con_therm_adc", "usb_con_therm_adc";
};


&qupv3_hub_i2c2 {
	status = "okay";
	qcom,clk-freq-out = <400000>;

	oplus_sc8547a:oplus,sc8547a@6F {
		status = "okay";
		compatible = "oplus,sc8547a";
		reg = <0x6F>;

		oplus,use_vooc_phy;
		oplus,use_ufcs_phy;
		oplus,vac_support;
		oplus_spec,irq_gpio = <&tlmm 59 0x00>;
		pinctrl-names = "charging_inter_active", "charging_inter_sleep";
		pinctrl-0 = <&charging_inter_active>;
		pinctrl-1 = <&charging_inter_sleep>;

		oplus,ic_type = <OPLUS_CHG_IC_VPHY>;
		oplus,ic_index = <0>;
		oplus,vooc-version = <VOOC_VERSION_5_0>;

		ocp_reg = <0xb>;
		ovp_reg = <0x36>;
		oplus_spec,voocphy_dual_cp_support;
		oplus_spec,slave_cp_enable_thr = <1400>;		//2000-100mA
		oplus_spec,slave_cp_disable_thr_high = <1100>;	//1500+100mA
		oplus_spec,voocphy_current_default = <61>;

		oplus_spec,svooc_cool_down_current_limit = <122 20 20 24 30 34 40 44 50 54 60 64 70 74>;
		oplus_spec,vooc_cool_down_current_limit = <61 20 20 24 30 34 40 44 50 54 60 64 70 74>;

		oplus_spec,vooc_multistep_initial_batt_temp = <1000>;
		oplus_spec,vooc_little_cool_temp = <160>;
		oplus_spec,vooc_cool_temp = <120>;
		oplus_spec,vooc_little_cold_temp = <50>;
		oplus_spec,vooc_normal_low_temp = <350>;
		oplus_spec,vooc_strategy_normal_current = <122>;
		oplus_spec,vooc_normal_to_little_cool_current = <100>;
		oplus_spec,vooc_over_high_temp = <510>;
		oplus_spec,vooc_low_temp = <0>;

		oplus_spec,vooc_high_temp = <500>;
		oplus_spec,vooc_low_soc = <0>;
		oplus_spec,vooc_high_soc = <90>;
		oplus_spec,vooc_normal_high_temp = <440>;
		oplus_spec,vooc_warm_vol_thr = <4000>;
		oplus_spec,vooc_warm_soc_thr = <50>;

		oplus_spec,vooc_strategy1_batt_high_temp0 = <385>;
		oplus_spec,vooc_strategy1_batt_high_temp1 = <395>;
		oplus_spec,vooc_strategy1_batt_high_temp2 = <420>;
		oplus_spec,vooc_strategy1_batt_low_temp2 = <410>;
		oplus_spec,vooc_strategy1_batt_low_temp1 = <385>;
		oplus_spec,vooc_strategy1_batt_low_temp0 = <375>;

		oplus_spec,vooc_strategy1_high_current0 = <80>;
		oplus_spec,vooc_strategy1_high_current1 = <61>;
		oplus_spec,vooc_strategy1_high_current2 = <40>;
		oplus_spec,vooc_strategy1_low_current2 = <40>;
		oplus_spec,vooc_strategy1_low_current1 = <61>;
		oplus_spec,vooc_strategy1_low_current0 = <80>;

		oplus_spec,vooc_strategy1_high_current0_vooc = <59>;
		oplus_spec,vooc_strategy1_high_current1_vooc = <59>;
		oplus_spec,vooc_strategy1_high_current2_vooc = <40>;
		oplus_spec,vooc_strategy1_low_current2_vooc = <59>;
		oplus_spec,vooc_strategy1_low_current1_vooc = <59>;
		oplus_spec,vooc_strategy1_low_current0_vooc = <59>;

		oplus_spec,voocphy_req_freq = <1860000 1923000 1986000 3302400>;
		oplus_spec,voocphy_freq_mincore = <1860000>;
		oplus_spec,voocphy_freq_midcore = <1923000>;
		oplus_spec,voocphy_freq_maxcore = <1986000>;
		oplus_spec,voocphy_current_change_timeout = <100>;
		oplus_spec,copycat_vooc_support;

		oplus_spec,voocphy_ibat_over_current = <13500>;
		oplus_spec,voocphy_svooc_cp_max_ibus = <3500>;
		oplus_spec,voocphy_vooc_cp_max_ibus = <3500>;
		oplus_spec,voocphy_cp_max_ibus = <3500>;

		oplus_spec,vooc_little_cold_full_voltage = <4465>;
		oplus_spec,vooc_cool_full_voltage = <4465>;
		oplus_spec,vooc_warm_full_voltage = <4130>;
		oplus_spec,vooc_1time_full_voltage = <4480>;
		oplus_spec,vooc_ntime_full_voltage = <4480>;
		oplus_spec,low_curr_full_t1 = <120>;
		oplus_spec,low_curr_full_t2 = <350>;
		oplus_spec,low_curr_full_t3 = <430>;
		oplus_spec,range1_low_curr_full = <1500 4490
						1400 4480
						1300 4470
						1200 4460
						1100 4450>;
		oplus_spec,range2_low_curr_full = <1600 4490
						1400 4480
						1300 4470
						1200 4460
						1100 4450>;

		svooc_batt_sys_curve = <0 1 0 1 0 0 0	// 4000mA
					1 1 1 1 0 0 0	// 4604mV
					0 0 1 1 0 1 0	// 2600mA
					1 1 1 1 0 0 0	// 4604mV
					0 0 0 1 0 1 1	// 1100mA
					1 1 1 1 0 0 0>;	// 4604mV

		vooc_batt_sys_curve =  <0 1 0 1 0 0 0	// 4000mA
					1 1 1 1 0 0 0	// 4604mV
					0 0 1 1 0 1 0	// 2600mA
					1 1 1 1 0 0 0	// 4604mV
					0 0 0 1 0 1 1	// 1100mA
					1 1 1 1 0 0 0>;	// 4604mV

		svooc_charge_strategy {
			strategy_soc_0_to_50 {
				strategy_temp_little_cold =	<4200 25 0 0 0
								 4455 20 0 0 0
								 4455 15 0 0 0
								 4465 10 1 0 0>;
				strategy_temp_cool =	<4180  40 0 0 0
								 4455 25 0 0 0
								 4455 20 0 0 0
								 4455 15 0 0 0
								 4465 10 1 0 0>;
				strategy_temp_little_cool =	<4200 50 0 1440 0
								 4400 30 0 0 0
								 4400 25 0 0 0
								 4470 20 0 0 0
								 4470 15 0 0 0
								 4480 10 1 0 0>;
				strategy_temp_normal_low =	<4250 61 0 840 0
								 4250 50 0 1440 0
								 4400 40 0 0 0
								 4470 30 0 0 0
								 4470 25 0 0 0
								 4470 20 0 0 0
								 4470 15 0 0 0
								 4480 10 1 0 0>;
				strategy_temp_normal_high =	<4250 50 0 1440 0
								 4400 40 0 0 0
								 4470 30 0 0 0
								 4470 25 0 0 0
								 4470 20 0 0 0
								 4470 15 0 0 0
								 4480 10 1 0 0>;
				strategy_temp_warm = <4130 20 1 0 0>;
			};

			strategy_soc_50_to_75 {
				strategy_temp_little_cold =	<4455 20 0 0 0
								 4455 15 0 0 0
								 4465 10 1 0 0>;
				strategy_temp_cool =	<4180 40 0 0 0
								 4455 25 0 0 0
								 4455 20 0 0 0
								 4455 15 0 0 0
								 4465 10 1 0 0>;
				strategy_temp_little_cool =	<4200 50 0 1440 0
								 4400 30 0 0 0
								 4400 25 0 0 0
								 4470 20 0 0 0
								 4470 15 0 0 0
								 4480 10 1 0 0>;
				strategy_temp_normal_low =	<4250 61 0 840 0
								 4250 50 0 1440 0
								 4400 40 0 0 0
								 4470 30 0 0 0
								 4470 25 0 0 0
								 4470 20 0 0 0
								 4470 15 0 0 0
								 4480 10 1 0 0>;
				strategy_temp_normal_high =	<4250 50 0 1440 0
								 4400 40 0 0 0
								 4470 30 0 0 0
								 4470 25 0 0 0
								 4470 20 0 0 0
								 4470 15 0 0 0
								 4480 10 1 0 0>;
				strategy_temp_warm = <4130 20 1 0 0>;
			};

			strategy_soc_75_to_85 {
				strategy_temp_little_cold =	<4455 20 0 0 0
								 4455 15 0 0 0
								 4465 10 1 0 0>;
				strategy_temp_cool =	<4455 25 0 0 0
                                                         4455 20 0 0 0
							 4455 15 0 0 0
							 4465 10 1 0 0>;
				strategy_temp_little_cool =	<4400 30 0 0 0
								 4400 25 0 0 0
								 4470 20 0 0 0
								 4470 15 0 0 0
								 4480 10 1 0 0>;
				strategy_temp_normal_low =	<4400 40 0 0 0
								 4470 30 0 0 0
								 4470 25 0 0 0
								 4470 20 0 0 0
								 4470 15 0 0 0
								 4480 10 1 0 0>;
				strategy_temp_normal_high =	<4400 40 0 0 0
								 4470 30 0 0 0
								 4470 25 0 0 0
								 4470 20 0 0 0
								 4470 15 0 0 0
								 4480 10 1 0 0>;
				strategy_temp_warm = <4130 20 1 0 0>;
			};

			strategy_soc_85_to_90 {
				strategy_temp_little_cold =	<4455 20 0 0 0
                                                                 4455 15 0 0 0
                                                                 4465 10 1 0 0>;
				strategy_temp_cool =	<4455 25 0 0 0
                                                         4455 20 0 0 0
                                                         4455 15 0 0 0
                                                         4465 10 1 0 0>;
				strategy_temp_little_cool =	<4470 20 0 0 0
								 4470 15 0 0 0
								 4480 10 1 0 0>;
				strategy_temp_normal_low =	<4470 30 0 0 0
								 4470 25 0 0 0
								 4470 20 0 0 0
								 4470 15 0 0 0
								 4480 10 1 0 0>;
				strategy_temp_normal_high =	<4470 30 0 0 0
								 4470 25 0 0 0
								 4470 20 0 0 0
								 4470 15 0 0 0
								 4480 10 1 0 0>;
				strategy_temp_warm = <4130 20 1 0 0>;
			};
		};

		vooc_charge_strategy {
			strategy_soc_0_to_50 {
				strategy_temp_little_cold =	<4420 28 0 0 0
								 4430 20 1 0 0>;
				strategy_temp_cool =	<4120 40 0 0 0
								 4420 30 0 0 0
								 4430 20 1 0 0>;
				strategy_temp_little_cool =	<4350 59 0 1800 0
								 4350 50 0 0 0
								 4470 40 0 0 0
								 4470 30 0 0 0
								 4480 20 1 0 0>;
				strategy_temp_normal_low =	<4450 59 0 1800 0
								 4450 50 0 0 0
								 4470 40 0 0 0
								 4470 30 0 0 0
								 4480 20 1 0 0>;
				strategy_temp_normal_high =	<4450 59 0 1800 0
								 4450 50 0 0 0
								 4470 40 0 0 0
								 4470 30 0 0 0
								 4480 20 1 0 0>;
				strategy_temp_warm = <4130 20 1 0 0>;
			};

			strategy_soc_50_to_75 {
				strategy_temp_little_cold =	<4430 20 1 0 0>;
				strategy_temp_cool =	<4420 30 0 0 0
								 4430 20 1 0 0>;
				strategy_temp_little_cool =	<4470 40 0 0 0
								 4470 30 0 0 0
								 4480 20 1 0 0>;
				strategy_temp_normal_low =	<4470 50 0 0 0
								 4470 40 0 0 0
								 4470 30 0 0 0
								 4480 20 1 0 0>;
				strategy_temp_normal_high =	<4470 50 0 0 0
								 4470 40 0 0 0
								 4470 30 0 0 0
								 4480 20 1 0 0>;
				strategy_temp_warm = <4130 20 1 0 0>;
			};

			strategy_soc_75_to_85 {
				strategy_temp_little_cold =	<4430 20 1 0 0>;
				strategy_temp_cool =	<4430 20 1 0 0>;
				strategy_temp_little_cool =	<4480 20 1 0 0>;
				strategy_temp_normal_low =	<4470 30 0 0 0
								4480 20 1 0 0>;
				strategy_temp_normal_high =	<4470 30 0 0 0
								4480 20 1 0 0>;
				strategy_temp_warm = <4130 20 1 0 0>;
			};

			strategy_soc_85_to_90 {
				strategy_temp_little_cold =	<4430 20 1 0 0>;
				strategy_temp_cool =	<4430 20 1 0 0>;
				strategy_temp_little_cool =	<4480 20 1 0 0>;
				strategy_temp_normal_low =	<4480 20 1 0 0>;
				strategy_temp_normal_high =	<4480 20 1 0 0>;
				strategy_temp_warm = <4130 20 1 0 0>;
			};
		};
		oplus_sc8547_cp: oplus,sc8547_cp {
			oplus,ic_type = <OPLUS_CHG_IC_CP>;
			oplus,ic_index = <0>;
			oplus,ic_func_group = <&sc8547_cp_groups>;
		};
	};
};

&qupv3_hub_i2c0 {
	status = "okay";
	clock-frequency = <400000>;
	oplus_sc8547_slave: sc8547-charger-slave@6F{
		status = "okay";
		compatible = "slave_vphy_sc8547";
		reg = <0x6F>;

		ocp_reg = <0xb>;
		ovp_reg = <0x36>;
		oplus_sc8547_slave_cp: oplus,sc8547_slave_cp {
			oplus,ic_type = <OPLUS_CHG_IC_CP>;
			oplus,ic_index = <1>;
			oplus,ic_func_group = <&sc8547_cp_groups>;
		};
	};
};

&qupv3_se15_2uart  {
	pinctrl-1 = <&qupv3_se7_2uart_sleep_backup>;
	status = "okay";
};

&tlmm  {
	qupv3_se7_2uart_sleep_backup:qupv3_se7_2uart_sleep_backup {
		mux {
			pins = "gpio30", "gpio31";
			function = "gpio";
		};

		config {
			pins = "gpio30", "gpio31";
			drive-strength = <2>;
			bias-disable;
			input-enable;
		};
	};
};

&tlmm {
	charging_inter_active: charging_inter_active {
		mux {
			pins = "gpio59";
			function = "gpio";
		};
		config {
			pins = "gpio59";
			bias-pull-up; /* NO pull */
			drive-strength = <2>; /* 2 MA */
			input-enable;
		};
	};

	charging_inter_sleep: charging_inter_sleep {
		mux {
			pins = "gpio59";
			function = "gpio";
		};
		config {
			pins = "gpio59";
			bias-pull-up; /* NO pull */
			drive-strength = <2>; /* 2 MA */
			input-enable;
		};
	};

	maxim_active: maxim_active {
		mux {
			pins = "gpio3";
			function = "gpio";
		};

		config {
			pins = "gpio3";
			bias-pull-up;
			drive-strength = <16>;
		};
	};
};

&pm8550_gpios {
	btb_temp_gpio_default: btb_temp_gpio_default {
		pins = "gpio4";
		function = "normal"; //normal
		bias-high-impedance;
		bias-disable;
	};
	svooc_mos_btb_therm {
		svooc_mos_btb_therm_default: svooc_mos_btb_therm_default {
			pins = "gpio12";
			function = "normal"; //normal
			bias-high-impedance;
			bias-disable;
		};
	};
};

&pm8550b_gpios {
	usbtemp_l_gpio_default: usbtemp_l_gpio_default {
		pins = "gpio5"; //GPIO 5
		function = "normal"; //normal
		bias-high-impedance; //DISABLE GPIO5 for ADC
		bias-disable;
	};
	usbtemp_r_gpio_default: usbtemp_r_gpio_default {
		pins = "gpio10"; //GPIO 10
		function = "normal"; //normal
		bias-high-impedance; //DISABLE GPIO10 for ADC
		bias-disable;
	};
	subboard_temp_gpio_default: subboard_temp_gpio_default {
		pins = "gpio6"; //GPIO 6
		function = "normal"; //normal
		bias-high-impedance; //DISABLE GPIO6 for ADC
		bias-disable;
	};
};

&pmk8550_vadc {
	pinctrl-0 = <&svooc_mos_btb_therm_default>;
	pinctrl-names = "default";

	svooc_mos_btb_therm {
		reg = <PM8550_ADC5_GEN3_AMUX4_GPIO12_100K_PU>;
		label = "svooc_mos_btb_therm";
		qcom,ratiometric;
		qcom,hw-settle-time = <200>;
		qcom,pre-scaling = <1 1>;
		qcom,adc-tm-type = <1>;
	};
	usb_temp_adc_l {
		reg = <PM8550B_ADC5_GEN3_AMUX2_GPIO5_100K_PU>;
		label = "usb_temp_adc_l";
		qcom,pre-scaling = <1 1>;
		qcom,ratiometric;
		qcom,hw-settle-time = <200>;
		qcom,scale-fn-type = <OPLUS_ADC_SCALE_HW_CALIB_DEFAULT>;
	};
	usb_temp_adc_r {
		reg = <PM8550B_ADC5_GEN3_AMUX_THM6_GPIO10_100K_PU>;
		label = "usb_temp_adc_r";
		qcom,pre-scaling = <1 1>;
		qcom,ratiometric;
		qcom,hw-settle-time = <200>;
		qcom,scale-fn-type = <OPLUS_ADC_SCALE_HW_CALIB_DEFAULT>;
	};
	pm8550b_wls_therm {
		qcom,adc-tm-type = <0>;
		qcom,scale-fn-type = <OPLUS_ADC_SCALE_HW_CALIB_DEFAULT>;
	};
	subboard_temp_adc {
		reg = <PM8550B_ADC5_GEN3_AMUX3_GPIO6_100K_PU>;
		label = "subboard_temp_adc";
		qcom,ratiometric;
		qcom,hw-settle-time = <200>;
		qcom,pre-scaling = <1 1>;
		qcom,adc-tm-type = <0>;
	};

	batt_con_therm_adc {
		reg = <PM8550_ADC5_GEN3_AMUX2_GPIO4_100K_PU>;
		label = "batt_con_therm_adc";
		qcom,ratiometric;
		qcom,hw-settle-time = <200>;
		qcom,pre-scaling = <1 1>;
		qcom,adc-tm-type = <0>;
	};
	usb_con_therm_adc {
		reg = <PM8550B_ADC5_GEN3_AMUX_THM4_USB_THERM_100K_PU>;
		label = "usb_con_therm_adc";
		qcom,ratiometric;
		qcom,hw-settle-time = <200>;
		qcom,pre-scaling = <1 1>;
		qcom,adc-tm-type = <1>;
		qcom,scale-fn-type = <OPLUS_ADC_SCALE_HW_CALIB_THERM_100K_PULLUP>;
	};
};

&thermal_zones {
	svooc_mos_btb_usr {
		polling-delay-passive = <0>;
		polling-delay = <0>;
		thermal-governor = "user_space";
		thermal-sensors = <&pmk8550_vadc PM8550_ADC5_GEN3_AMUX4_GPIO12_100K_PU>;
		wake-capable-sensor;
		trips {
			active-config0 {
				temperature = <125000>;
				hysteresis = <1000>;
				type = "passive";
			};
		};
	};
};

&battery_charger {
	io-channels	= <&pmk8550_vadc PM8550B_ADC5_GEN3_AMUX3_GPIO6_100K_PU>,
					<&pmk8550_vadc PM8550_ADC5_GEN3_AMUX2_GPIO4_100K_PU>,
					<&pmk8550_vadc PM8550B_ADC5_GEN3_AMUX_THM4_USB_THERM_100K_PU>;
	io-channel-names = "subboard_temp_adc", "batt_con_therm_adc", "usb_con_therm_adc";
};

&pm8550vs_e_gpios {
	dischg_enable: dischg_enable {
		pins = "gpio6";
		function = "normal";
		bias-disable;
		power-source = <0>;
		output-high;
		qcom,drive-strength = <3>;
	};
	dischg_disable: dischg_disable {
		pins = "gpio6";
		function = "normal";
		bias-disable;
		power-source = <0>;
		output-low;
		qcom,drive-strength = <3>;
	};
};

&soc {
	maxim_encryption_gauge: maxim_gauge {
		status = "ok";
		compatible = "oplus-maxim";
		pinctrl-names = "maxim_active";
		pinctrl-0 = <&maxim_active>;
		data-gpio = <&tlmm 3 0x00>;
		gpio-addr-set-out = <0xF103000>;
		gpio-addr-set-in = <0xF103000>;
		gpio-addr-level_high = <0xF103004>;
		gpio-addr-level_low = <0xF103004>;
		gpio-addr-data-in = <0xF103004>;
		gpio-addr-offset = <0x0>;

		gpio-set-out-val = <0x1bc3>;
		gpio-set-in-val = <0x19c3>;
		gpio_level_high_val = <0x3>;
		gpio_level_low_val = <0x0>;

		oplus,batt_info = /bits/ 8 <0x36 0x31 0x31 0x33 0x30 0x37 0x30 0x30 0x30 0x30 0x33 0x30
                                            0x36 0x31 0x31 0x33 0x30 0x37 0x30 0x30 0x30 0x30 0x33 0x31>;

		oplus,ic_type = <OPLUS_CHG_IC_GAUGE>;
		oplus,ic_index = <1>;
	};
};

&qupv3_hub_i2c3 {
	status = "ok";
	pencil-wireless-charger@41 {
		status = "ok";
		compatible = "oplus,wls-charger-cps8601";
		reg = <0x41 0>;

		pinctrl-names = "wls_charge_int_active", "wls_charge_int_sleep", "wls_charge_int_default",
				"wls_sleep_active", "wls_sleep_sleep", "wls_sleep_default",
				"wls_scan_active", "wls_scan_sleep", "wls_scan_default",
				"wls_off_state_active", "wls_off_state_sleep", "wls_off_state_default",
				"wls_sw_en_active", "wls_sw_en_sleep", "wls_sw_en_default";

		pinctrl-0 = <&wls_charge_int_active>;
		pinctrl-1 = <&wls_charge_int_sleep>;
		pinctrl-2 = <&wls_charge_int_default>;
		pinctrl-3 = <&wls_sleep_active>;
		pinctrl-4 = <&wls_sleep_sleep>;
		pinctrl-5 = <&wls_sleep_default>;
		pinctrl-6 = <&wls_scan_active>;
		pinctrl-7 = <&wls_scan_sleep>;
		pinctrl-8 = <&wls_scan_default>;
		pinctrl-9 = <&wls_off_state_active>;
		pinctrl-10 = <&wls_off_state_sleep>;
		pinctrl-11 = <&wls_off_state_default>;
		pinctrl-12 = <&wls_sw_en_active>;
		pinctrl-13 = <&wls_sw_en_sleep>;
		pinctrl-14 = <&wls_sw_en_default>;

		qcom,cps_wls_int-gpio = <&tlmm 12 0x00>;
		qcom,wls_sleep-gpio = <&tlmm 15 0x00>;
		qcom,wls_scan-gpio = <&tlmm 85 0x00>;
		qcom,wls_off_state-gpio = <&tlmm 111 0x00>;
		qcom,wls_sw_en-gpio = <&tlmm 10 0x00>;

		qcom,ocp_threshold = <500>;
		qcom,ovp_threshold = <12000>;
		qcom,lvp_threshold = <4000>;
		qcom,pcop_threshold1 = <700>;
		qcom,pcop_threshold2 = <500>;
		qcom,fod_threshold = <400>;
		rx,soc_threshold = <90>;
		qcom,pen_is_supply_by_hboost = <1>;
		qcom,hboost_default_volt_mv = <5800>;
	};
};

&tlmm {
	wls_sw_en_active: wls_sw_en_active {
		mux {
			pins = "gpio10";
			function = "gpio";
		};

		config {
			pins = "gpio10";
			bias-pull-up;
			drive-strength = <2>;
		};
	};

	wls_sw_en_sleep: wls_sw_en_sleep {
		mux {
			pins = "gpio10";
			function = "gpio";
		};

		config {
			pins = "gpio10";
			bias-pull-down;
			drive-strength = <2>;
		};
	};

	wls_sw_en_default: wls_sw_en_default {
		mux {
			pins = "gpio10";
			function = "gpio";
		};

		config {
			pins = "gpio10";
			bias-pull-down;
			drive-strength = <2>;
		};
	};

	wls_charge_int_active: wls_charge_int_active {
		mux {
			pins = "gpio12";
			function = "gpio";
		};

		config {
			pins = "gpio12";
			bias-pull-up;
			input-enable;
			drive-strength = <2>;
		};
	};

	wls_charge_int_sleep: wls_charge_int_sleep {
		mux {
			pins = "gpio12";
			function = "gpio";
		};

		config {
			pins = "gpio12";
			bias-pull-down;
			input-enable;
			drive-strength = <2>;
		};
	};

	wls_charge_int_default: wls_charge_int_default {
		mux {
			pins = "gpio12";
			function = "gpio";
		};

		config {
			pins = "gpio12";
			bias-pull-down;
			input-enable;
			drive-strength = <2>;
		};
	};

	wls_sleep_active: wls_sleep_active {
		mux {
			pins = "gpio15";
			function = "gpio";
		};

		config {
			pins = "gpio15";
			bias-pull-up;
			drive-strength = <2>;
		};
	};

	wls_sleep_sleep: wls_sleep_sleep {
		mux {
			pins = "gpio15";
			function = "gpio";
		};

		config {
			pins = "gpio15";
			bias-pull-down;
			drive-strength = <2>;
		};
	};

	wls_sleep_default: wls_sleep_default {
		mux {
			pins = "gpio15";
			function = "gpio";
		};

		config {
			pins = "gpio15";
			bias-pull-up;
			drive-strength = <2>;
		};
	};

	wls_scan_active: wls_scan_active {
		mux {
			pins = "gpio85";
			function = "gpio";
		};

		config {
			pins = "gpio85";
			bias-pull-up;
			drive-strength = <2>;
		};
	};

	wls_scan_sleep: wls_scan_sleep {
		mux {
			pins = "gpio85";
			function = "gpio";
		};

		config {
			pins = "gpio85";
			bias-pull-down;
			drive-strength = <2>;
		};
	};

	wls_scan_default: wls_scan_default {
		mux {
			pins = "gpio85";
			function = "gpio";
		};

		config {
			pins = "gpio85";
			bias-pull-up;
			drive-strength = <2>;
		};
	};

	wls_off_state_active: wls_off_state_active {
		mux {
			pins = "gpio111";
			function = "gpio";
		};

		config {
			pins = "gpio111";
			bias-pull-up;
			drive-strength = <2>;
		};
	};

	wls_off_state_sleep: wls_off_state_sleep {
		mux {
			pins = "gpio111";
			function = "gpio";
		};

		config {
			pins = "gpio111";
			bias-pull-down;
			drive-strength = <2>;
		};
	};

	wls_off_state_default: wls_off_state_default {
		mux {
			pins = "gpio111";
			function = "gpio";
		};

		config {
			pins = "gpio111";
			bias-pull-up;
			drive-strength = <2>;
		};
	};
};

&wireless_pen_hboost {
	compatible = "oplus,wireless_pen_glink";
};

